VERSION ""

NS_ :

BS_:

BU_:

BO_ 3221225472 VECTOR__INDEPENDENT_SIG_MSG: 0 Vector__XXX
 SG_ MotorOverrideMux : 0|8@1+ (1,0) [0|255] "" Vector__XXX

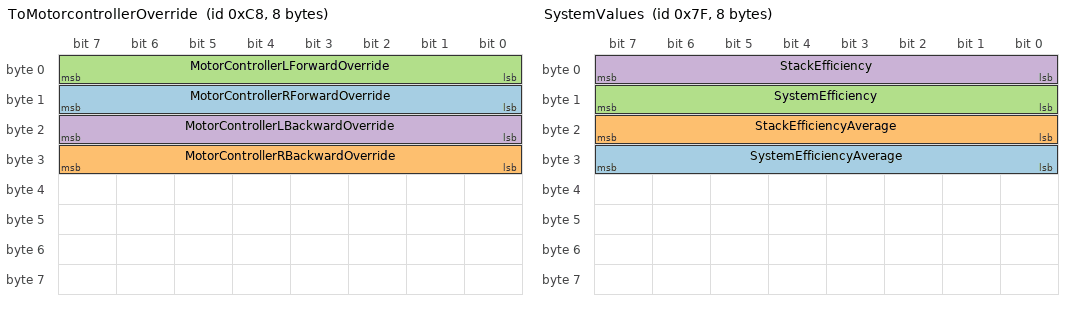
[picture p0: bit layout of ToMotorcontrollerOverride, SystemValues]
BO_ 200 ToMotorcontrollerOverride: 8 Vector__XXX
 SG_ MotorControllerRForwardOverride : 8|8@1+ (1,0) [0|255] "" Vector__XXX
 SG_ MotorControllerRBackwardOverride : 24|8@1+ (1,0) [0|255] "" Vector__XXX
 SG_ MotorControllerLForwardOverride : 0|8@1+ (1,0) [0|255] "" Vector__XXX
 SG_ MotorControllerLBackwardOverride : 16|8@1+ (1,0) [0|255] "" Vector__XXX

BO_ 127 SystemValues: 8 Vector__XXX
 SG_ SystemEfficiencyAverage : 24|8@1+ (1,0) [0|255] "" Vector__XXX
 SG_ StackEfficiencyAverage : 16|8@1+ (1,0) [0|255] "" Vector__XXX
 SG_ SystemEfficiency : 8|8@1+ (1,0) [0|255] "" Vector__XXX
 SG_ StackEfficiency : 0|8@1+ (1,0) [0|255] "" Vector__XXX

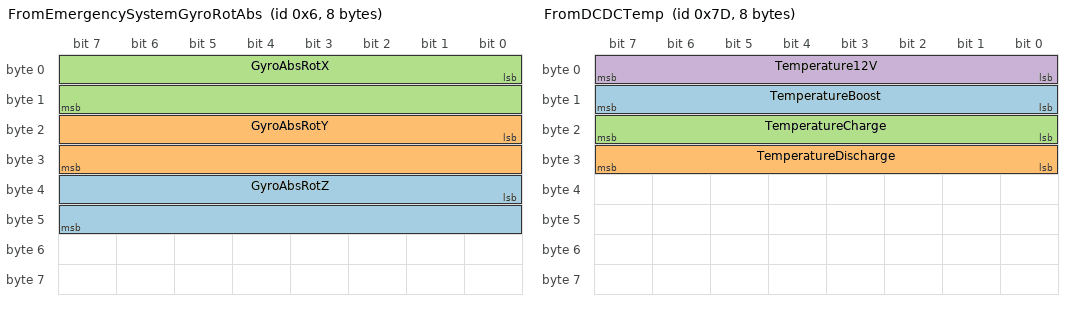
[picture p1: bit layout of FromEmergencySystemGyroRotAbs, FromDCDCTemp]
BO_ 6 FromEmergencySystemGyroRotAbs: 8 Vector__XXX
 SG_ GyroAbsRotZ : 32|16@1+ (1,0) [0|65535] "" Vector__XXX
 SG_ GyroAbsRotY : 16|16@1+ (1,0) [0|65535] "" Vector__XXX
 SG_ GyroAbsRotX : 0|16@1+ (1,0) [0|65535] "" Vector__XXX

BO_ 125 FromDCDCTemp: 8 Vector__XXX
 SG_ TemperatureBoost : 8|8@1+ (1,0) [0|255] "" Vector__XXX
 SG_ TemperatureDischarge : 24|8@1+ (1,0) [0|255] "" Vector__XXX
 SG_ TemperatureCharge : 16|8@1+ (1,0) [0|255] "" Vector__XXX
 SG_ Temperature12V : 0|8@1+ (1,0) [0|255] "" Vector__XXX

BO_ 112 FromEmergencySystemGPS: 8 Vector__XXX
 SG_ long : 32|32@1- (1,0) [-3.4E+038|3.4E+038] "" Vector__XXX
 SG_ lat : 0|32@1- (1,0) [-3.4E+038|3.4E+038] "" Vector__XXX

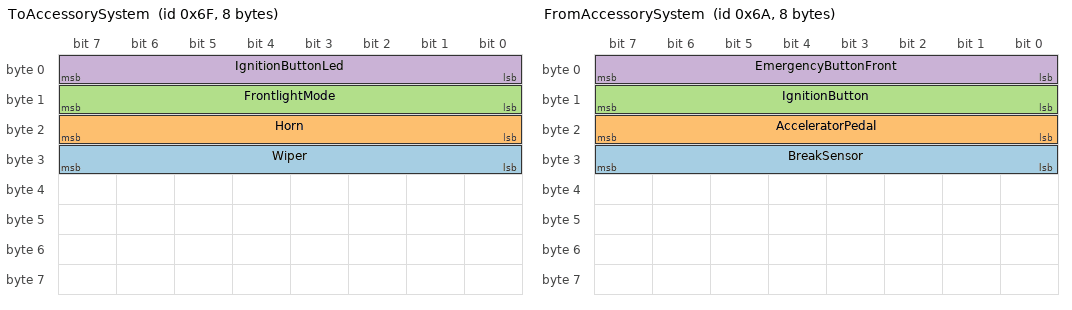
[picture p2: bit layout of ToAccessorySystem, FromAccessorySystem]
BO_ 111 ToAccessorySystem: 8 Vector__XXX
 SG_ Wiper : 24|8@1+ (1,0) [0|255] "" Vector__XXX
 SG_ Horn : 16|8@1+ (1,0) [0|255] "" Vector__XXX
 SG_ FrontlightMode : 8|8@1+ (1,0) [0|255] "" Vector__XXX
 SG_ IgnitionButtonLed : 0|8@1+ (1,0) [0|255] "" Vector__XXX

BO_ 108 FromMotorControllerR: 2 Vector__XXX
 SG_ MotorControllerRRPM : 0|16@1+ (1,0) [0|65535] "" Vector__XXX

BO_ 107 FromMotorControllerL: 2 Vector__XXX
 SG_ MotorControllerLRPM : 0|16@1+ (1,0) [0|65535] "" Vector__XXX

BO_ 106 FromAccessorySystem: 8 Vector__XXX
 SG_ BreakSensor : 24|8@1+ (1,0) [0|255] "" Vector__XXX
 SG_ AcceleratorPedal : 16|8@1+ (1,0) [0|255] "" Vector__XXX
 SG_ IgnitionButton : 8|8@1+ (1,0) [0|255] "" Vector__XXX
 SG_ EmergencyButtonFront : 0|8@1+ (1,0) [0|255] "" Vector__XXX

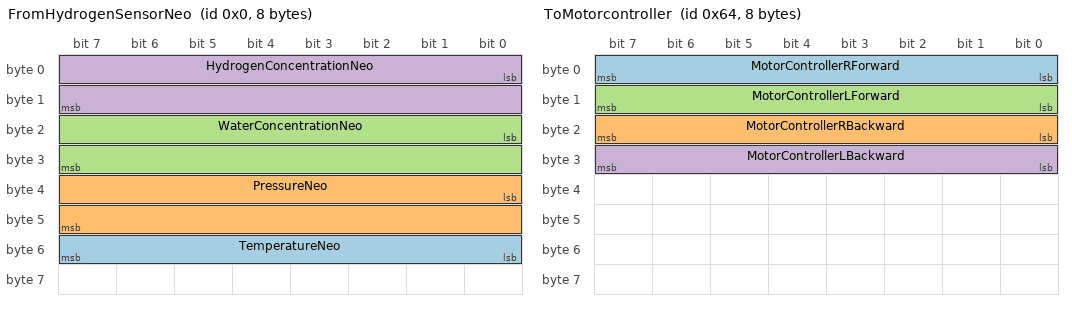
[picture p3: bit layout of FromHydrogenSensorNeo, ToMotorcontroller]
BO_ 0 FromHydrogenSensorNeo: 8 Vector__XXX
 SG_ TemperatureNeo : 48|8@1+ (1,0) [0|255] "" Vector__XXX
 SG_ PressureNeo : 32|16@1+ (1,0) [0|65535] "" Vector__XXX
 SG_ WaterConcentrationNeo : 16|16@1+ (1,0) [0|65535] "" Vector__XXX
 SG_ HydrogenConcentrationNeo : 0|16@1+ (1,0) [0|65535] "" Vector__XXX

BO_ 100 ToMotorcontroller: 8 Vector__XXX
 SG_ MotorControllerRForward : 0|8@1+ (1,0) [0|255] "" Vector__XXX
 SG_ MotorControllerRBackward : 16|8@1+ (1,0) [0|255] "" Vector__XXX
 SG_ MotorControllerLForward : 8|8@1+ (1,0) [0|255] "" Vector__XXX
 SG_ MotorControllerLBackward : 24|8@1+ (1,0) [0|255] "" Vector__XXX

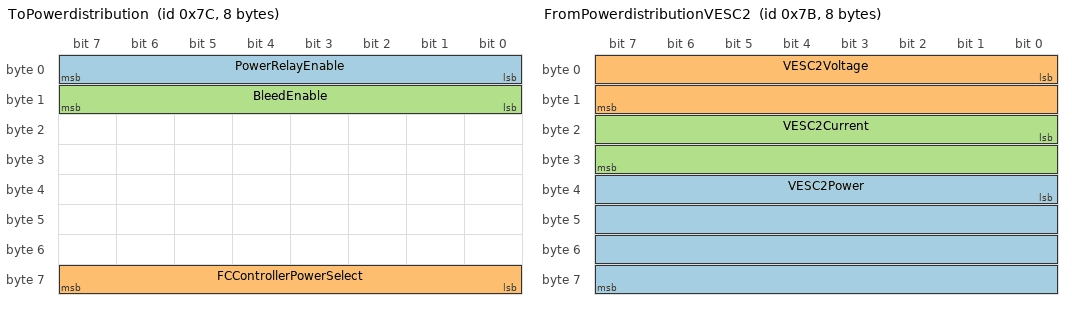
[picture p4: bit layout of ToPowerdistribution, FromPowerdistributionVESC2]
BO_ 124 ToPowerdistribution: 8 Vector__XXX
 SG_ PowerRelayEnable : 0|8@1+ (1,0) [0|255] "" Vector__XXX
 SG_ FCControllerPowerSelect : 56|8@1+ (1,0) [0|255] "" Vector__XXX
 SG_ BleedEnable : 8|8@1+ (1,0) [0|255] "" Vector__XXX

BO_ 123 FromPowerdistributionVESC2: 8 Vector__XXX
 SG_ VESC2Power : 32|32@1+ (1,0) [0|4294967295] "" Vector__XXX
 SG_ VESC2Voltage : 0|16@1+ (1,0) [0|65535] "" Vector__XXX
 SG_ VESC2Current : 16|16@1+ (1,0) [0|65535] "" Vector__XXX

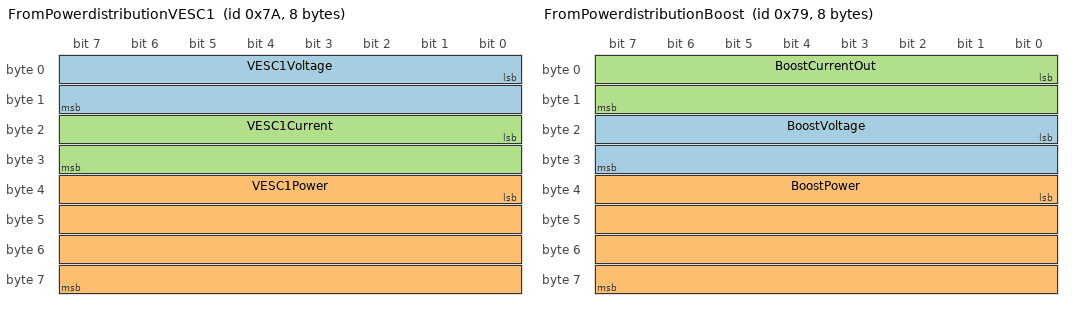
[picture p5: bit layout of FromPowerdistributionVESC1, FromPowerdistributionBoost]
BO_ 122 FromPowerdistributionVESC1: 8 Vector__XXX
 SG_ VESC1Voltage : 0|16@1+ (1,0) [0|65535] "" Vector__XXX
 SG_ VESC1Power : 32|32@1+ (1,0) [0|4294967295] "" Vector__XXX
 SG_ VESC1Current : 16|16@1+ (1,0) [0|65535] "" Vector__XXX

BO_ 121 FromPowerdistributionBoost: 8 Vector__XXX
 SG_ BoostVoltage : 16|16@1+ (1,0) [0|65535] "" Vector__XXX
 SG_ BoostPower : 32|32@1+ (1,0) [0|4294967295] "" Vector__XXX
 SG_ BoostCurrentOut : 0|16@1+ (1,0) [0|65535] "" Vector__XXX

BO_ 120 FromPowerdistributionSC: 8 Vector__XXX
 SG_ SCVoltage : 0|16@1+ (1,0) [0|65535] "" Vector__XXX
 SG_ SCChargeCurrent : 16|16@1+ (1,0) [0|65535] "" Vector__XXX

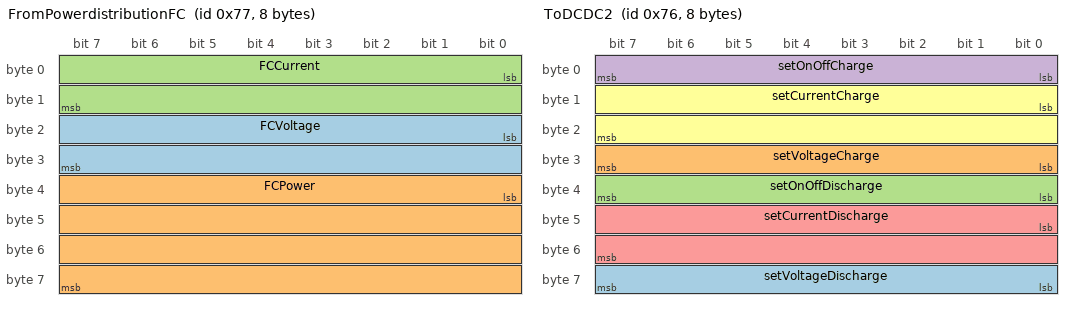
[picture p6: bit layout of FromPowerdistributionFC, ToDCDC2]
BO_ 119 FromPowerdistributionFC: 8 Vector__XXX
 SG_ FCVoltage : 16|16@1+ (1,0) [0|65535] "" Vector__XXX
 SG_ FCPower : 32|32@1+ (1,0) [0|4294967295] "" Vector__XXX
 SG_ FCCurrent : 0|16@1+ (1,0) [0|65535] "" Vector__XXX

BO_ 118 ToDCDC2: 8 Vector__XXX
 SG_ setVoltageDischarge : 56|8@1+ (1,0) [0|255] "" Vector__XXX
 SG_ setVoltageCharge : 24|8@1+ (1,0) [0|255] "" Vector__XXX
 SG_ setOnOffDischarge : 32|8@1+ (1,0) [0|255] "" Vector__XXX
 SG_ setOnOffCharge : 0|8@1+ (1,0) [0|255] "" Vector__XXX
 SG_ setCurrentDischarge : 40|16@1+ (1,0) [0|65535] "" Vector__XXX
 SG_ setCurrentCharge : 8|16@1+ (1,0) [0|65535] "" Vector__XXX

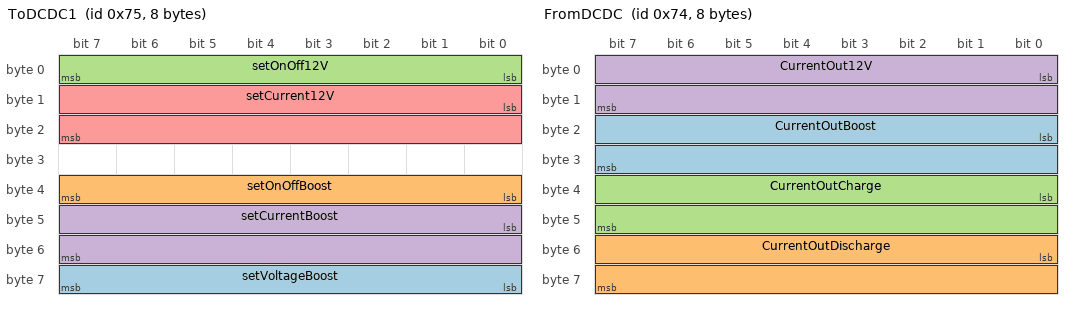
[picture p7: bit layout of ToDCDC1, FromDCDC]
BO_ 117 ToDCDC1: 8 Vector__XXX
 SG_ setVoltageBoost : 56|8@1+ (1,0) [0|255] "" Vector__XXX
 SG_ setOnOffBoost : 32|8@1+ (1,0) [0|255] "" Vector__XXX
 SG_ setOnOff12V : 0|8@1+ (1,0) [0|255] "" Vector__XXX
 SG_ setCurrentBoost : 40|16@1+ (1,0) [0|65535] "" Vector__XXX
 SG_ setCurrent12V : 8|16@1+ (1,0) [0|65535] "" Vector__XXX

BO_ 116 FromDCDC: 8 Vector__XXX
 SG_ CurrentOutBoost : 16|16@1+ (1,0) [0|255] "" Vector__XXX
 SG_ CurrentOutDischarge : 48|16@1+ (1,0) [0|255] "" Vector__XXX
 SG_ CurrentOutCharge : 32|16@1+ (1,0) [0|255] "" Vector__XXX
 SG_ CurrentOut12V : 0|16@1+ (1,0) [0|255] "" Vector__XXX

BO_ 115 FromSidekick: 8 Vector__XXX
 SG_ H2Massflow : 0|32@1+ (1,0) [0|4294967295] "" Vector__XXX

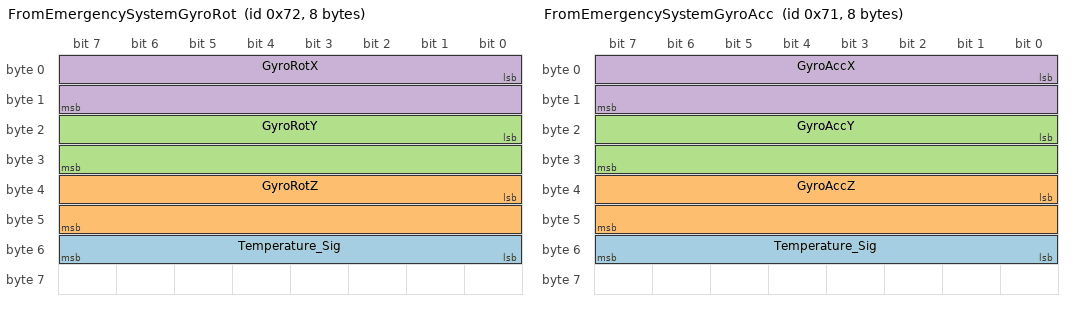
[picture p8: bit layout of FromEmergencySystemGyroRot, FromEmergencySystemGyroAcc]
BO_ 114 FromEmergencySystemGyroRot: 8 Vector__XXX
 SG_ Temperature_Sig : 48|8@1+ (1,0) [0|255] "" Vector__XXX
 SG_ GyroRotZ : 32|16@1+ (1,0) [0|65535] "" Vector__XXX
 SG_ GyroRotY : 16|16@1+ (1,0) [0|65535] "" Vector__XXX
 SG_ GyroRotX : 0|16@1+ (1,0) [0|65535] "" Vector__XXX

BO_ 113 FromEmergencySystemGyroAcc: 8 Vector__XXX
 SG_ Temperature_Sig : 48|8@1+ (1,0) [0|255] "" Vector__XXX
 SG_ GyroAccZ : 32|16@1+ (1,0) [0|65535] "" Vector__XXX
 SG_ GyroAccY : 16|16@1+ (1,0) [0|65535] "" Vector__XXX
 SG_ GyroAccX : 0|16@1+ (1,0) [0|255] "" Vector__XXX

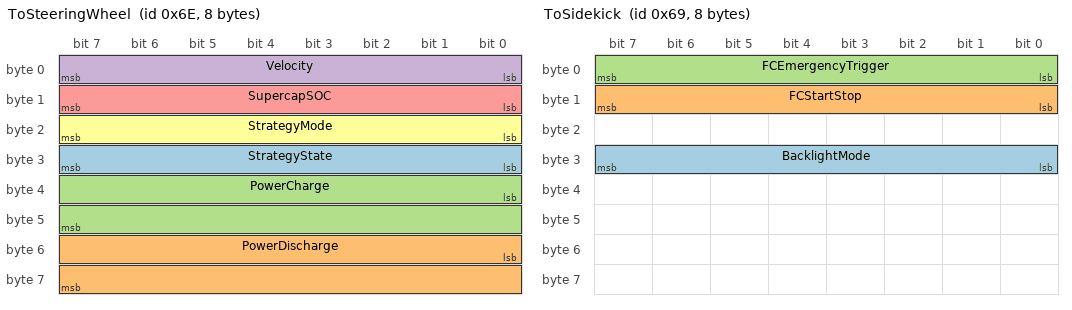
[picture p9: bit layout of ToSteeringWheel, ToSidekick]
BO_ 110 ToSteeringWheel: 8 Vector__XXX
 SG_ StrategyState : 24|8@1+ (1,0) [0|255] "" Vector__XXX
 SG_ PowerDischarge : 48|16@1+ (1,0) [0|65535] "" Vector__XXX
 SG_ PowerCharge : 32|16@1+ (1,0) [0|65535] "" Vector__XXX
 SG_ Velocity : 0|8@1+ (1,0) [0|255] "" Vector__XXX
 SG_ SupercapSOC : 8|8@1+ (1,0) [0|255] "" Vector__XXX
 SG_ StrategyMode : 16|8@1+ (1,0) [0|255] "" Vector__XXX

BO_ 109 FromSteeringWheel: 8 Vector__XXX
 SG_ SteeringWheelButtons : 0|16@1+ (1,0) [0|65535] "" Vector__XXX
 SG_ Accelerator : 16|8@1+ (1,0) [0|255] "" Vector__XXX

BO_ 105 ToSidekick: 8 Vector__XXX
 SG_ BacklightMode : 24|8@1+ (1,0) [0|255] "" Vector__XXX
 SG_ FCStartStop : 8|8@1+ (1,0) [0|255] "" Vector__XXX
 SG_ FCEmergencyTrigger : 0|8@1+ (1,0) [0|255] "" Vector__XXX

BO_ 103 ToEmergencySystem: 8 Vector__XXX
 SG_ EmergencyRedLED : 0|8@1+ (1,0) [0|255] "" Vector__XXX
 SG_ EmergencyGreenLED : 8|8@1+ (1,0) [0|255] "" Vector__XXX

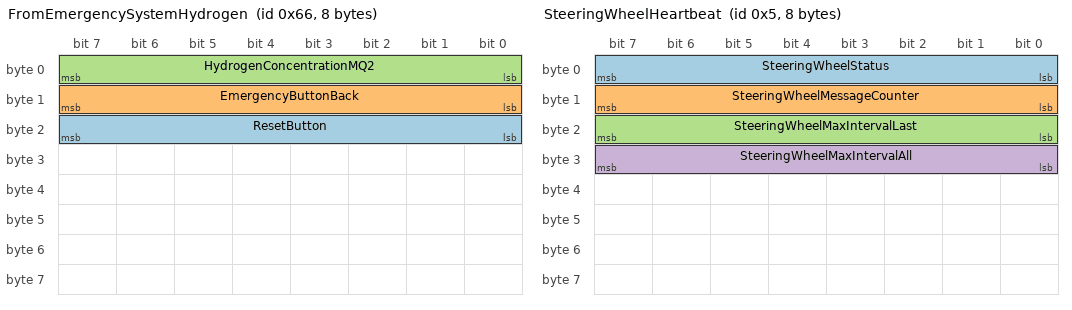
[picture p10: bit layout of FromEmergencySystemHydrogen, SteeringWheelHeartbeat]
BO_ 102 FromEmergencySystemHydrogen: 8 Vector__XXX
 SG_ ResetButton : 16|8@1+ (1,0) [0|255] "" Vector__XXX
 SG_ EmergencyButtonBack : 8|8@1+ (1,0) [0|255] "" Vector__XXX
 SG_ HydrogenConcentrationMQ2 : 0|8@1+ (1,0) [0|255] "" Vector__XXX

BO_ 5 SteeringWheelHeartbeat: 8 Vector__XXX
 SG_ SteeringWheelStatus : 0|8@1+ (1,0) [0|255] "" Vector__XXX
 SG_ SteeringWheelMessageCounter : 8|8@1+ (1,0) [0|255] "" Vector__XXX
 SG_ SteeringWheelMaxIntervalLast : 16|8@1+ (1,0) [0|255] "" Vector__XXX
 SG_ SteeringWheelMaxIntervalAll : 24|8@1+ (1,0) [0|255] "" Vector__XXX

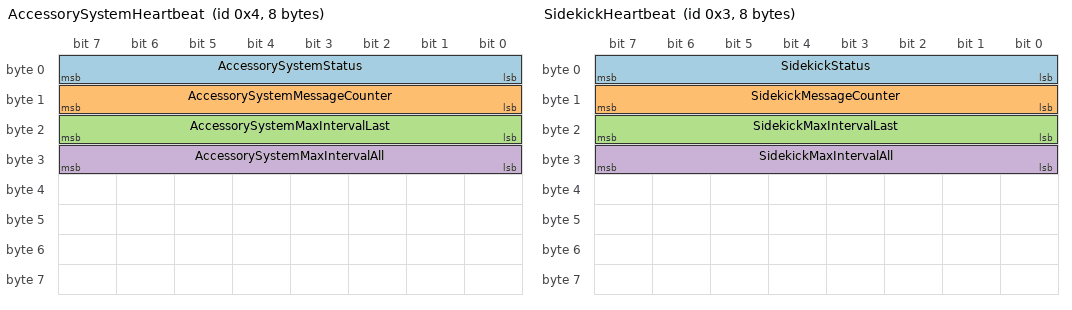
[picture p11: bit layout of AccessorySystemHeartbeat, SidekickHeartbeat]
BO_ 4 AccessorySystemHeartbeat: 8 Vector__XXX
 SG_ AccessorySystemStatus : 0|8@1+ (1,0) [0|255] "" Vector__XXX
 SG_ AccessorySystemMessageCounter : 8|8@1+ (1,0) [0|255] "" Vector__XXX
 SG_ AccessorySystemMaxIntervalLast : 16|8@1+ (1,0) [0|255] "" Vector__XXX
 SG_ AccessorySystemMaxIntervalAll : 24|8@1+ (1,0) [0|255] "" Vector__XXX

BO_ 3 SidekickHeartbeat: 8 Vector__XXX
 SG_ SidekickStatus : 0|8@1+ (1,0) [0|255] "" Vector__XXX
 SG_ SidekickMessageCounter : 8|8@1+ (1,0) [0|255] "" Vector__XXX
 SG_ SidekickMaxIntervalLast : 16|8@1+ (1,0) [0|255] "" Vector__XXX
 SG_ SidekickMaxIntervalAll : 24|8@1+ (1,0) [0|255] "" Vector__XXX

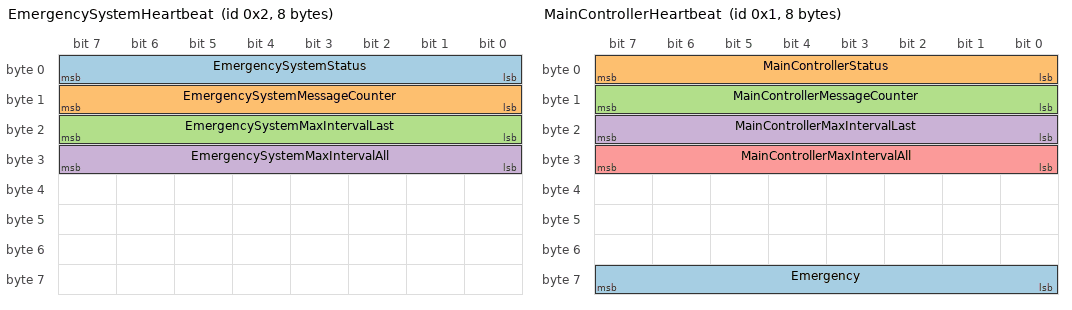
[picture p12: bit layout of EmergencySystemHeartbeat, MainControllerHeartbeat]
BO_ 2 EmergencySystemHeartbeat: 8 Vector__XXX
 SG_ EmergencySystemStatus : 0|8@1+ (1,0) [0|255] "" Vector__XXX
 SG_ EmergencySystemMessageCounter : 8|8@1+ (1,0) [0|255] "" Vector__XXX
 SG_ EmergencySystemMaxIntervalLast : 16|8@1+ (1,0) [0|255] "" Vector__XXX
 SG_ EmergencySystemMaxIntervalAll : 24|8@1+ (1,0) [0|255] "" Vector__XXX

BO_ 1 MainControllerHeartbeat: 8 Vector__XXX
 SG_ Emergency : 56|8@1+ (1,0) [0|255] "" Vector__XXX
 SG_ MainControllerStatus : 0|8@1+ (1,0) [0|255] "" Vector__XXX
 SG_ MainControllerMessageCounter : 8|8@1+ (1,0) [0|255] "" Vector__XXX
 SG_ MainControllerMaxIntervalLast : 16|8@1+ (1,0) [0|255] "" Vector__XXX
 SG_ MainControllerMaxIntervalAll : 24|8@1+ (1,0) [0|255] "" Vector__XXX

CM_ BO_ 3221225472 "This is a message for not used signals, created by Vector CANdb++ DBC OLE DB Provider.";
BA_DEF_  "BusType" STRING ;
BA_DEF_DEF_  "BusType" "CAN";
SIG_VALTYPE_ 112 long : 1;
SIG_VALTYPE_ 112 lat : 1;
